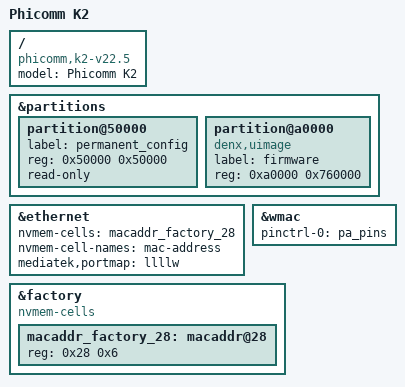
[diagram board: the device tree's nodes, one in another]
#include "mt7620a_phicomm_k2x.dtsi"

/ {
	compatible = "phicomm,k2-v22.5", "ralink,mt7620a-soc";
	model = "Phicomm K2";
};

&partitions {
	partition@50000 {
		label = "permanent_config";
		reg = <0x50000 0x50000>;
		read-only;
	};

	partition@a0000 {
		compatible = "denx,uimage";
		label = "firmware";
		reg = <0xa0000 0x760000>;
	};
};

&ethernet {
	nvmem-cells = <&macaddr_factory_28>;
	nvmem-cell-names = "mac-address";

	mediatek,portmap = "llllw";
};

&wmac {
	pinctrl-names = "default";
	pinctrl-0 = <&pa_pins>;
};

&factory {
	compatible = "nvmem-cells";
	#address-cells = <1>;
	#size-cells = <1>;

	macaddr_factory_28: macaddr@28 {
		reg = <0x28 0x6>;
	};
};
